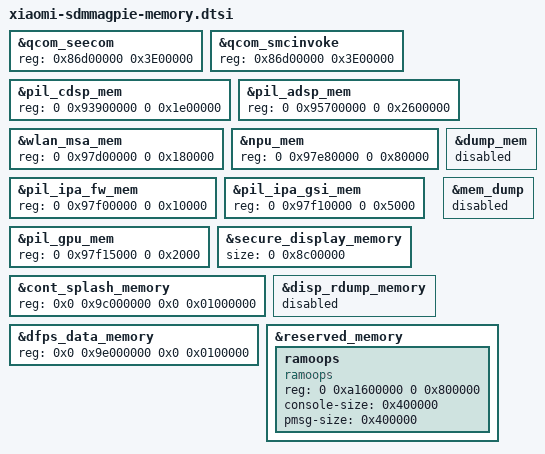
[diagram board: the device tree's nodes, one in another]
/*
 * Copyright (C) 2020 The LineageOS Project
 *
 */

&qcom_seecom {
    reg = <0x86d00000 0x3E00000>;
};

&qcom_smcinvoke {
    reg = <0x86d00000 0x3E00000>;
};

&pil_cdsp_mem {
    reg = <0 0x93900000 0 0x1e00000>;
};

&pil_adsp_mem {
    reg = <0 0x95700000 0 0x2600000>;
};

&wlan_msa_mem {
    reg = <0 0x97d00000 0 0x180000>;
};

&npu_mem {
    reg = <0 0x97e80000 0 0x80000>;
};

&pil_ipa_fw_mem {
    reg = <0 0x97f00000 0 0x10000>;
};

&pil_ipa_gsi_mem {
    reg = <0 0x97f10000 0 0x5000>;
};

&pil_gpu_mem {
    reg = <0 0x97f15000 0 0x2000>;
};

&secure_display_memory {
    size = <0 0x8c00000>;
};

/* Reduce cont splash, display ramdump and dfps data
 * buffer size to 1000000.
 * 1000000 is taken from sm6150.dtsi.
 */
&cont_splash_memory {
    reg = <0x0 0x9c000000 0x0 0x01000000>;
};

&disp_rdump_memory {
    status = "disabled";
};

&dfps_data_memory {
    reg = <0x0 0x9e000000 0x0 0x0100000>;
};

&dump_mem {
    status = "disabled";
};

&mem_dump {
    status = "disabled";
};

&reserved_memory {
    ramoops {
        compatible = "ramoops";
        reg = <0 0xa1600000 0 0x800000>;
        console-size = <0x400000>;
        pmsg-size = <0x400000>;
    };
};
